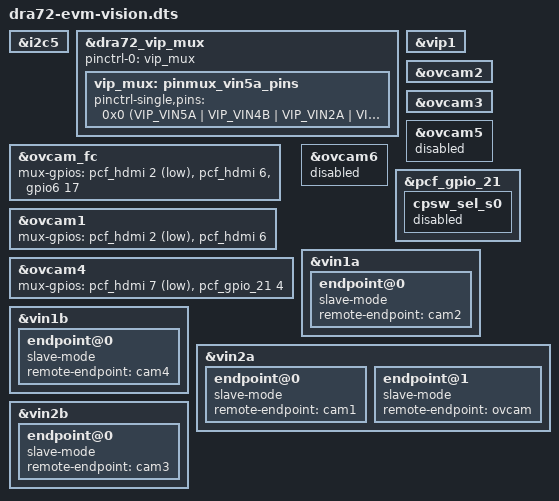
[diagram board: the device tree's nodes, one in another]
/*
 * Copyright (C) 2013 Texas Instruments Incorporated - http://www.ti.com/
 *
 * This program is free software; you can redistribute it and/or modify
 * it under the terms of the GNU General Public License version 2 as
 * published by the Free Software Foundation.
 */

#include "dra72-evm.dts"

i2cexp: &i2c5 {
};

#include "dra7xx-vision.dtsi"

/*
 * Following is the mapping of the cameras and video ports:
 *
 * +-------+--------------------+--------+---------+---------+---------+---------+
 * | Video |   VIP port name    | LVDS   | DES I2C | Remote  | SER I2C | CAM I2C |
 * | Port  | Inst Slice  Port   | Camera | Addr    | I2C bus | Alias   | Alias   |
 * +-------+--------------------+--------+---------+---------+---------+---------+
 * | vin2a | VIP1 Slice1 Port A |  cam1  |   0x60  |   11    |   0x74  |   0x38  |
 * | vin1a | VIP1 Slice0 Port A |  cam2  |   0x64  |   12    |   0x75  |   0x39  |
 * | vin2b | VIP1 Slice1 Port B |  cam3  |   0x68  |   13    |   0x76  |   0x3A  |
 * | vin1b | VIP1 Slice0 Port B |  cam4  |   0x6C  |   14    |   0x77  |   0x3B  |
 * +-------+--------------------+--------+---------+---------+---------+---------+
 *
 * For easier access, all the remote devices can be accessed using the remote bus
 * No need to remember the aliases - instead use real addresses on remote bus.
 * For example, the i2c address for remote serializer is 0x58 and camera is 0x30
 * So this can be accessed as 11-0058 and 11-0030 (11 is the remote bus)
 */

&dra72_vip_mux {

	pinctrl-names = "default";
	pinctrl-0 = <&vip_mux>;

	/* Following is the mapping of interfaces
	 * vin1A <= vin5A (remapped)
	 * vin1B <= vin4B (remapped, only available option)
	 * vin2A <= vin2A (default)
	 * vin2B <= vin3B (default)
	 */
	vip_mux: pinmux_vin5a_pins {
		pinctrl-single,pins = <
			0x0	(VIP_VIN5A | VIP_VIN4B | VIP_VIN2A | VIP_VIN3B)
		>;
	};
};

&vip1 {
	status = "okay";
};

&ovcam_fc {
	/* Select between onboard OV10633 camera and daughter card vin
	 * Also enable power for the OVcamera externally */
	mux-gpios =
		<&pcf_hdmi 2	GPIO_ACTIVE_LOW>,	/* VIN2_S0 */
		<&pcf_hdmi 6	GPIO_ACTIVE_HIGH>,	/* VIN2_S2 */
		<&gpio6 17	GPIO_ACTIVE_HIGH>;	/* OV_PWDN */
};

&ovcam1 {
	/* Select between onboard OV10633 camera and daughter card vin */
	mux-gpios =
		<&pcf_hdmi 2	GPIO_ACTIVE_LOW>,	/* VIN2_S0 */
		<&pcf_hdmi 6	GPIO_ACTIVE_HIGH>;	/* VIN2_S2 */
};

&ovcam2 {
	/* No board muxes */
};

&ovcam3 {
	/* No board muxes */
};

/* This is to not hog the GPIO
 * We need to set the gpio from the camera driver
 * Note that this will disable the ethernet */
/delete-node/ &sel_enet_mux_hog;

&ovcam4 {
	/* No board muxes */
	mux-gpios =
		<&pcf_hdmi 7	GPIO_ACTIVE_LOW>,	/* SEL_VIN4_MUX_S0 */
		<&pcf_gpio_21 4	GPIO_ACTIVE_HIGH>;	/* SEL_ENET_MUX_S0 */
};

&ovcam5 {
	status = "disabled";
};

&ovcam6 {
	status = "disabled";
};

&pcf_gpio_21 {
	cpsw_sel_s0 {
		status = "disabled";
	};
};

&vin1a {
	status = "okay";
	endpoint@0 {
		slave-mode;
		remote-endpoint = <&cam2>;
	};
};

&vin1b {
	status = "okay";
	endpoint@0 {
		slave-mode;
		remote-endpoint = <&cam4>;
	};
};

&vin2a {
	status = "okay";
	endpoint@0 {
		slave-mode;
		remote-endpoint = <&cam1>;
	};
	endpoint@1 {
		slave-mode;
		remote-endpoint = <&ovcam>;
	};
};

&vin2b {
	status = "okay";
	endpoint@0 {
		slave-mode;
		remote-endpoint = <&cam3>;
	};
};
